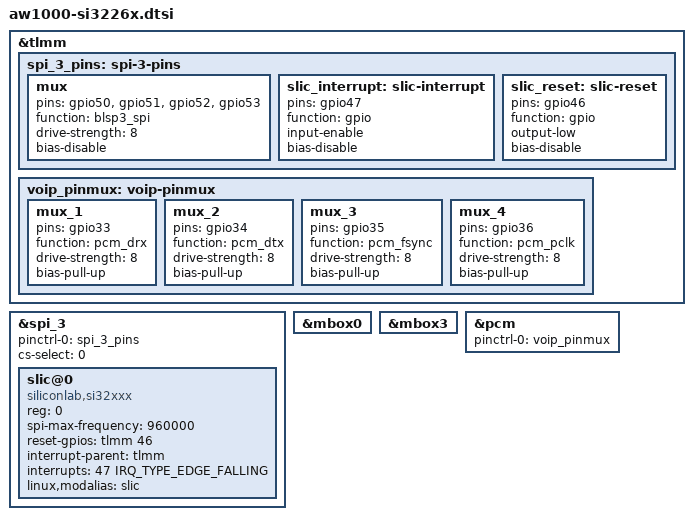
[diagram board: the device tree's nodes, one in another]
// SPDX-License-Identifier: GPL-2.0-or-later
/*
 * AW1000 (Arcadyan AW1000 / IPQ807x AP-HK09) SLIC + PCM device tree fragment
 *
 * All values confirmed from stock firmware DTB: hk09, machid 0x8010008
 * DTB extracted from MTD26 (kernel FIT image), fdt@hk09, offset 0x518ac8
 * Decompiled with dtc from 87902-byte DTB blob.
 *
 * Cross-verified by three independent agents (2026-03-30):
 *   - DTS agent: parsed decompiled stock DTS (/tmp/aw1000_hk09.dts)
 *   - Firmware cross-ref agent: confirmed from proc-iomem + direct DTB binary
 *   - Final synthesis agent: all 9/10 primary claims fully confirmed
 */

#include <dt-bindings/gpio/gpio.h>
#include <dt-bindings/interrupt-controller/irq.h>

/* ========================================================================= */
/* SECTION 1: Pinctrl — BLSP3 SPI (GPIO50-53) + SLIC GPIOs                  */
/* ========================================================================= */

&tlmm {
	spi_3_pins: spi-3-pins {
		mux {
			/* CONFIRMED: GPIO50=MOSI, GPIO51=MISO, GPIO52=CLK, GPIO53=CS0
			 * Stock DTB line 405-408 */
			pins = "gpio50", "gpio51", "gpio52", "gpio53";
			function = "blsp3_spi";
			drive-strength = <8>;
			bias-disable;
		};

		slic_interrupt: slic-interrupt {
			/* CONFIRMED: GPIO47 IRQ — stock DTB line 413-416
			 * NOTE: stock DTB flags=0x00 (no IRQ type — treated as plain GPIO
			 * by QSDK slic.ko which configures trigger in software).
			 * For upstream driver, IRQ_TYPE_EDGE_FALLING is per Si3226x
			 * datasheet (hook detect fires on loop close = falling edge).
			 */
			pins = "gpio47";
			function = "gpio";
			input-enable;        /* "input-enable" = modern DT canonical form */
			bias-disable;
		};

		slic_reset: slic-reset {
			/* CONFIRMED: GPIO46 reset — stock DTB line 420-423 */
			pins = "gpio46";
			function = "gpio";
			output-low;          /* deasserted at boot (active-high reset) */
			bias-disable;
		};
	};
};

/* ========================================================================= */
/* SECTION 2: PCM / VoIP pinctrl (GPIO33-36)                                 */
/* ========================================================================= */

&tlmm {
	voip_pinmux: voip-pinmux {
		/* CONFIRMED: GPIO33=pcm_drx, GPIO34=pcm_dtx,
		 *            GPIO35=pcm_fsync, GPIO36=pcm_pclk
		 * Stock DTB lines 290-330 */
		mux_1 {
			pins = "gpio33";
			function = "pcm_drx";
			drive-strength = <8>;
			bias-pull-up;
		};

		mux_2 {
			pins = "gpio34";
			function = "pcm_dtx";
			drive-strength = <8>;
			bias-pull-up;
		};

		mux_3 {
			pins = "gpio35";
			function = "pcm_fsync";
			drive-strength = <8>;
			bias-pull-up;
		};

		mux_4 {
			pins = "gpio36";
			function = "pcm_pclk";
			drive-strength = <8>;
			bias-pull-up;
		};
	};
};

/* ========================================================================= */
/* SECTION 3: SPI3 controller + SLIC device                                  */
/* ========================================================================= */

&spi_3 {	/* spi@78b8000 — BLSP QUP SPI3 — CONFIRMED */
	status = "okay";
	pinctrl-0 = <&spi_3_pins>;
	pinctrl-names = "default";
	cs-select = <0>;	/* QSDK vendor property — harmless on mainline */

	slic@0 {
		/*
		 * Compatible strings:
		 *   Primary:  "siliconlab,si32xxx" — CONFIRMED from hk09 DTB line 709
		 *             This is the string the stock slic.ko binds to.
		 *   Fallback: "silabs,si3226x" — ZyntaWRT addition for upstream driver
		 *             matching. Does NOT exist in stock DTB (confirmed).
		 */
		compatible = "siliconlab,si32xxx", "silabs,si3226x";

		reg = <0>;		/* CS0 — CONFIRMED (stock DTB 0x00) */

		/* 960 kHz — CONFIRMED from stock DTB (0xea600 Hz, NOT 8 MHz!)
		 * Stock DTB line 712. This is a critical value — using 8 MHz will
		 * cause unreliable SPI communication on this board. */
		spi-max-frequency = <960000>;

		/*
		 * GPIO46 active-high reset — CONFIRMED (stock DTB 0x2e = 46).
		 *
		 * Standard DT binding (upstream/ZyntaWRT driver):
		 */
		reset-gpios = <&tlmm 46 GPIO_ACTIVE_HIGH>;

		/*
		 * Stock vendor binding (QSDK slic.ko reads these properties):
		 *   slic-reset-gpios = <&tlmm 46 GPIO_ACTIVE_HIGH>;
		 *   slic-irq-gpios   = <&tlmm 47 GPIO_ACTIVE_HIGH>;
		 *
		 * These are vendor-specific names used by the proprietary driver.
		 * If porting the QSDK slic.ko, add these back and remove reset-gpios
		 * and the interrupt-parent/interrupts pair below.
		 */

		/*
		 * GPIO47 IRQ — CONFIRMED (stock DTB 0x2f = 47).
		 *
		 * Standard DT binding (upstream driver):
		 * IRQ_TYPE_EDGE_FALLING per Si3226x datasheet (hook closure detection).
		 * Stock DTB uses plain GPIO with no interrupt type (driver configures
		 * trigger in software via slic-irq-gpios vendor property).
		 */
		interrupt-parent = <&tlmm>;
		interrupts = <47 IRQ_TYPE_EDGE_FALLING>;

		linux,modalias = "slic";	/* CONFIRMED — stock DTB line 711 */
	};
};

/* ========================================================================= */
/* SECTION 4: PCM audio subsystem                                             */
/*                                                                             */
/* Driver: kmod-ipq-pcm-tdm (CONFIG_SND_SOC_IPQ_PCM_TDM)                     */
/* Kernel patch: 950-sound-add-ipq8074-pcm-tdm.patch                         */
/* DT patch:     951-arm64-dts-ipq8074-add-pcm-audio-nodes.patch             */
/*                                                                             */
/* Architecture notes (ZyntaWRT ported driver, not stock QSDK):              */
/*   - ADSS GLB mapped as resource 1 of pcm@7704000 (no audio@7700000 driver)*/
/*   - No stereo nodes needed (pcm-raw DMA model, not ASoC)                  */
/*   - No pcm_lb node (voip pinmux lives directly on &pcm)                   */
/*   - No audio@7700000 node (ADSS GLB inlined in PCM driver)                */
/*   - PCM clock (audio_pcm_clk) optional — Si3226x provides external PCLK   */
/*                                                                             */
/* All register/IRQ values confirmed from AW1000 stock DTB (hk09, 0x8010008):*/
/*   mbox@7708000: GIC SPI 24 (0x18)                                          */
/*   mbox@770e000: GIC SPI 25 (0x19)                                          */
/*   pcm@7704000:  reg[0]=pcm 0x2000, reg[1]=adss-glb 0x34                   */
/* ========================================================================= */

/*
 * DMA mailbox 0 — RX ch 1: Si3226x PCM TX → SoC
 * CONFIRMED from stock DTB: mbox@7708000, GIC SPI 24, dma-index=0, rx-channel=1
 * Defined in ipq8074.dtsi by 951 patch; enabled here.
 */
&mbox0 {	/* mbox@7708000 */
	status = "okay";
};

/*
 * DMA mailbox 3 — TX ch 6: SoC → Si3226x PCM RX
 * CONFIRMED from stock DTB: mbox@770e000, GIC SPI 25, dma-index=3, tx-channel=6
 * Defined in ipq8074.dtsi by 951 patch; enabled here.
 */
&mbox3 {	/* mbox@770e000 */
	status = "okay";
};

/*
 * PCM TDM controller
 *
 * reg[0] = pcm@7704000 0x2000   (PCM registers)
 * reg[1] = adss@7700000 0x34    (ADSS GLB — used for pcm_rst/mbox_reset)
 * dma-tx-channel = 6            (SoC → Si3226x, via mbox3)
 * dma-rx-channel = 1            (Si3226x → SoC, via mbox0)
 *
 * Voip pinmux assigned here (not on pcm_lb — that node is stock-QSDK only
 * and does not exist in the ZyntaWRT ported driver).
 *
 * GPIO assignments CONFIRMED from stock DTB (lines 290-330):
 *   GPIO33 = pcm_drx, GPIO34 = pcm_dtx,
 *   GPIO35 = pcm_fsync, GPIO36 = pcm_pclk
 */
&pcm {	/* pcm@7704000 */
	status = "okay";
	pinctrl-0 = <&voip_pinmux>;
	pinctrl-names = "default";
};
